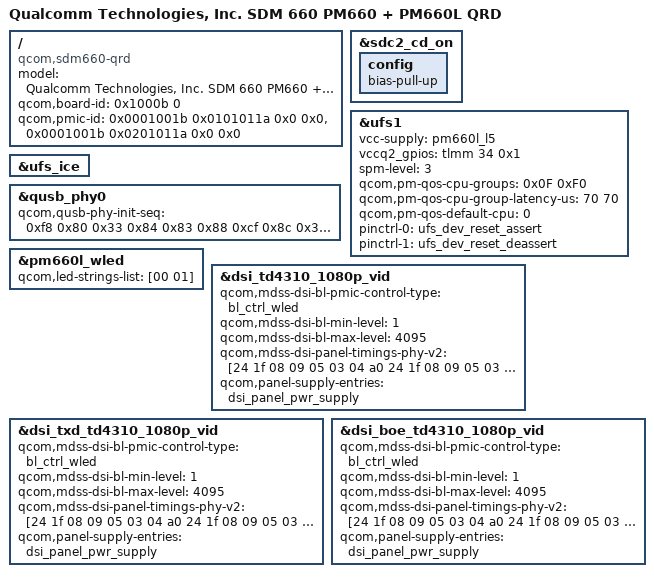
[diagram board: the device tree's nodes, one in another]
/* Copyright (c) 2016-2017, The Linux Foundation. All rights reserved.
 *
 * This program is free software; you can redistribute it and/or modify
 * it under the terms of the GNU General Public License version 2 and
 * only version 2 as published by the Free Software Foundation.
 *
 * This program is distributed in the hope that it will be useful,
 * but WITHOUT ANY WARRANTY; without even the implied warranty of
 * MERCHANTABILITY or FITNESS FOR A PARTICULAR PURPOSE.  See the
 * GNU General Public License for more details.
 */


/dts-v1/;

#include "sdm660.dtsi"
#include "sdm660-qrd.dtsi"
#include "oscar-pinctrl.dtsi"
#include "oscar-audio.dtsi"
#include "oscar-camera.dtsi"
#include "oscar-charging.dtsi"
#include "oscar-fingerprint.dtsi"
#include "oscar-haptics.dtsi"
#include "oscar-key.dtsi"
#include "oscar-leds.dtsi"
#include "oscar-panels.dtsi"
#include "oscar-common.dtsi"
#include "osborn-leds.dtsi"
#include "osborn-unused-gpio.dtsi"

/ {
	model = "Qualcomm Technologies, Inc. SDM 660 PM660 + PM660L QRD";
	compatible = "qcom,sdm660-qrd", "qcom,sdm660", "qcom,qrd";
	qcom,board-id = <0x1000b 0>;
	qcom,pmic-id = <0x0001001b 0x0101011a 0x0 0x0>,
			<0x0001001b 0x0201011a 0x0 0x0>;
};

&sdc2_cd_on {
	config {
		/delete-property/ bias-disable;
		bias-pull-up;
	};
};

&ufs1 {
	vcc-supply = <&pm660l_l5>;
	/delete-property/ vccq2-supply;
	vccq2_gpios = <&tlmm 34 0x1>;

	spm-level = <3>;

	/* PM QoS */
	qcom,pm-qos-cpu-groups = <0x0F 0xF0>;
	qcom,pm-qos-cpu-group-latency-us = <70 70>;
	qcom,pm-qos-default-cpu = <0>;

	pinctrl-names = "dev-reset-assert", "dev-reset-deassert";
	pinctrl-0 = <&ufs_dev_reset_assert>;
	pinctrl-1 = <&ufs_dev_reset_deassert>;

	status = "ok";
};

&ufs_ice {
	status = "ok";
};

&qusb_phy0 {
	qcom,qusb-phy-init-seq = <0xf8 0x80
				0x33 0x84
				0x83 0x88
				0xcf 0x8c
				0x30 0x08
				0x79 0x0c
				0x21 0x10
				0x14 0x9c
				0x9f 0x1c
				0x00 0x18>;
};

&pm660l_wled {
	qcom,led-strings-list = [00 01];
};

&dsi_td4310_1080p_vid {
	qcom,mdss-dsi-bl-pmic-control-type = "bl_ctrl_wled";
	qcom,mdss-dsi-bl-min-level = <1>;
	qcom,mdss-dsi-bl-max-level = <4095>;
	qcom,mdss-dsi-panel-timings-phy-v2 = [24 1f 08 09 05 03 04 a0
		24 1f 08 09 05 03 04 a0
		24 1f 08 09 05 03 04 a0
		24 1f 08 09 05 03 04 a0
		24 1b 08 09 05 03 04 a0];
	qcom,panel-supply-entries = <&dsi_panel_pwr_supply>;
};

&dsi_txd_td4310_1080p_vid {
	qcom,mdss-dsi-bl-pmic-control-type = "bl_ctrl_wled";
	qcom,mdss-dsi-bl-min-level = <1>;
	qcom,mdss-dsi-bl-max-level = <4095>;
	qcom,mdss-dsi-panel-timings-phy-v2 = [24 1f 08 09 05 03 04 a0
		24 1f 08 09 05 03 04 a0
		24 1f 08 09 05 03 04 a0
		24 1f 08 09 05 03 04 a0
		2f 1b 08 09 05 03 04 a0];
	qcom,panel-supply-entries = <&dsi_panel_pwr_supply>;
};

&dsi_boe_td4310_1080p_vid {
	qcom,mdss-dsi-bl-pmic-control-type = "bl_ctrl_wled";
	qcom,mdss-dsi-bl-min-level = <1>;
	qcom,mdss-dsi-bl-max-level = <4095>;
	qcom,mdss-dsi-panel-timings-phy-v2 = [24 1f 08 09 05 03 04 a0
		24 1f 08 09 05 03 04 a0
		24 1f 08 09 05 03 04 a0
		24 1f 08 09 05 03 04 a0
		24 1b 08 09 05 03 04 a0];
	qcom,panel-supply-entries = <&dsi_panel_pwr_supply>;
};
